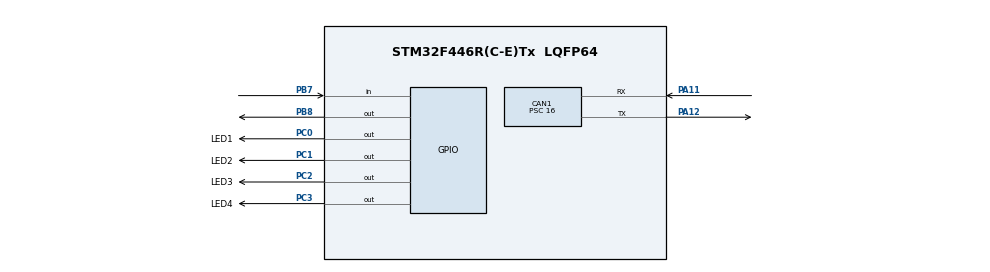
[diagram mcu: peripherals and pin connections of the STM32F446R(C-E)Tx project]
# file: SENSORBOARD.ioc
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CAN1.BS1=CAN_BS1_9TQ
CAN1.BS2=CAN_BS2_8TQ
CAN1.CalculateBaudRate=55555
CAN1.CalculateTimeBit=18000
CAN1.CalculateTimeQuantum=1000.0
CAN1.Prescaler=16
Mcu.Family=STM32F4
Mcu.Name=STM32F446R(C-E)Tx
Mcu.Package=LQFP64
NVIC.CAN1_RX0_IRQn=true\:0\:0\:false\:false\:true\:true\:true\:true
NVIC.CAN1_RX1_IRQn=true\:0\:0\:false\:false\:true\:true\:true\:true
NVIC.CAN1_TX_IRQn=true\:0\:0\:false\:false\:true\:true\:true\:true
NVIC.PriorityGroup=NVIC_PRIORITYGROUP_4
PA11.Mode=CAN_Activate
PA11.Signal=CAN1_RX
PA12.Mode=CAN_Activate
PA12.Signal=CAN1_TX
PB7.Signal=GPIO_Input
PB8.Signal=GPIO_Output
PC0.GPIO_Label=LED1
PC0.Signal=GPIO_Output
PC1.GPIO_Label=LED2
PC1.Signal=GPIO_Output
PC2.GPIO_Label=LED3
PC2.Signal=GPIO_Output
PC3.GPIO_Label=LED4
PC3.Signal=GPIO_Output
ProjectManager.HeapSize=0x200
ProjectManager.StackSize=0x400
ProjectManager.TargetToolchain=STM32CubeIDE
RCC.CortexFreq_Value=16000000
RCC.USBFreq_Value=96000000
RCC.VCOOutputFreq_Value=192000000
board=custom

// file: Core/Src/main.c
/* USER CODE BEGIN Header */
/**
  ******************************************************************************
  * @file           : main.c
  * @brief          : Main program body
  ******************************************************************************
  * @attention
  *
  * Copyright (c) 2025 STMicroelectronics.
  * All rights reserved.
  *
  * This software is licensed under terms that can be found in the LICENSE file
  * in the root directory of this software component.
  * If no LICENSE file comes with this software, it is provided AS-IS.
  *
  ******************************************************************************
  */
/* USER CODE END Header */
#include "main.h"
#include "can.h"
#include "gpio.h"

/* USER CODE BEGIN Includes */
#include "HX711.h"
/* USER CODE END Includes */

void SystemClock_Config(void);

/* USER CODE BEGIN 0 */
hx711_t hx;
float weight;
/* USER CODE END 0 */

int main(void)
{

  /* MCU Configuration--------------------------------------------------------*/

  /* Reset of all peripherals, Initializes the Flash interface and the Systick. */
  HAL_Init();

  /* Configure the system clock */
  SystemClock_Config();

  /* Initialize all configured peripherals */
  MX_GPIO_Init();
  MX_CAN1_Init();

  /* Infinite loop */
  /* USER CODE BEGIN WHILE */
  init_weight(&hx);
  while (1)
  {
    /* USER CODE END WHILE */
	  weight =measure_weight(hx);
  }
}

void SystemClock_Config(void)
{
  RCC_OscInitTypeDef RCC_OscInitStruct = {0};
  RCC_ClkInitTypeDef RCC_ClkInitStruct = {0};

  /** Configure the main internal regulator output voltage
  */
  __HAL_RCC_PWR_CLK_ENABLE();
  __HAL_PWR_VOLTAGESCALING_CONFIG(PWR_REGULATOR_VOLTAGE_SCALE3);

  /** Initializes the RCC Oscillators according to the specified parameters
  * in the RCC_OscInitTypeDef structure.
  */
  RCC_OscInitStruct.OscillatorType = RCC_OSCILLATORTYPE_HSI;
  RCC_OscInitStruct.HSIState = RCC_HSI_ON;
  RCC_OscInitStruct.HSICalibrationValue = RCC_HSICALIBRATION_DEFAULT;
  RCC_OscInitStruct.PLL.PLLState = RCC_PLL_NONE;
  if (HAL_RCC_OscConfig(&RCC_OscInitStruct) != HAL_OK)
  {
    Error_Handler();
  }

  /** Initializes the CPU, AHB and APB buses clocks
  */
  RCC_ClkInitStruct.ClockType = RCC_CLOCKTYPE_HCLK|RCC_CLOCKTYPE_SYSCLK
                              |RCC_CLOCKTYPE_PCLK1|RCC_CLOCKTYPE_PCLK2;
  RCC_ClkInitStruct.SYSCLKSource = RCC_SYSCLKSOURCE_HSI;
  RCC_ClkInitStruct.AHBCLKDivider = RCC_SYSCLK_DIV1;
  RCC_ClkInitStruct.APB1CLKDivider = RCC_HCLK_DIV1;
  RCC_ClkInitStruct.APB2CLKDivider = RCC_HCLK_DIV1;

  if (HAL_RCC_ClockConfig(&RCC_ClkInitStruct, FLASH_LATENCY_0) != HAL_OK)
  {
    Error_Handler();
  }
}

void Error_Handler(void)
{
  __disable_irq();
  while (1)
  {
  }
}
